# PLLDIG_CTRL register map
Vendor: Texas Instruments
Peripheral module from a debugger description file (folder xwrl64xx).
Registers are 32-bit, read-write, no defined reset value unless marked. A register's access mark holds for its fields unless they carry their own. Offsets are as the file gives them; lines under a group give offsets from that group; [hi:lo] are bit positions; {n}, {i} and the like mark numbered series; 'fields as' and 'values as' point back to an identical list; <NAME> marks a mode.

## PLLDIG_CTRL
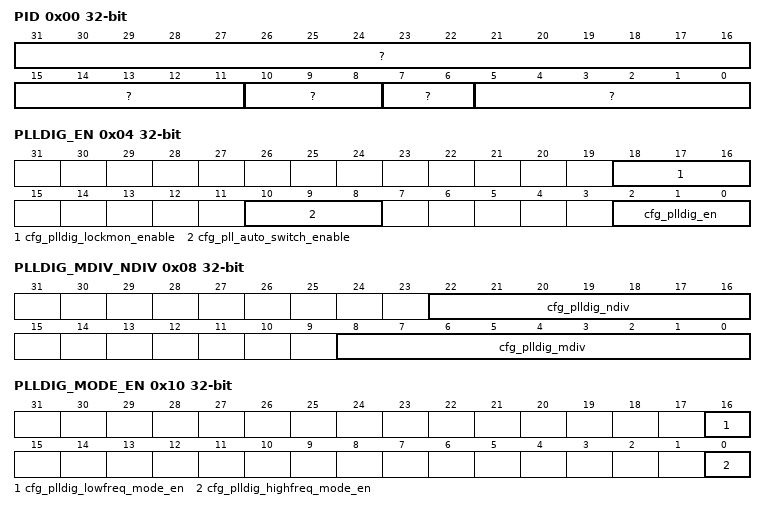
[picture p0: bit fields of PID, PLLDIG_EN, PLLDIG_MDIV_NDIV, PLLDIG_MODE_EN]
0x00 PID ro
  [31:16] ?, [15:11] ?, [10:8] ?, [7:6] ?, [5:0] ?
0x04 PLLDIG_EN
  [18:16] cfg_plldig_lockmon_enable — PLL DIG lockmon enable 0x0 = PLL DIG lockmon disbale 0x7 = PLL DIG lockmon enable
  [10:8] cfg_pll_auto_switch_enable — PLL DIG and APLL auto switch enable 0x0 = PLL DIG wont be auto turn off when APLL is enable 0x7 = PLL DIG will be auto turn off when APLL is enable
  [2:0] cfg_plldig_en — PLL DIG enable 0x0 = PLL DIG disable 0x7 = PLL DIG enable
0x08 PLLDIG_MDIV_NDIV
  [22:16] cfg_plldig_ndiv — NDIV value for the PLL DIG Input clock divider settings .NDIV value directly programs the 7-bit pre- divider. Divide value ranges from 2 to 127. NDIV value has to be chosen based on the REF_CLKIN frequency so as to get the internal reference frequency of the PLL closest to 2Mhz
  [8:0] cfg_plldig_mdiv — MDIV value for the PLL DIG Feedback divider settings. MDIV value directly programs the 9-bit feedback divider. Divide value ranges from 2 to 511. MDIV value has to be chosen to generate the required clock out frequency from the 2Mhz internal PLL reference
0x0C PLLDIG_CTRL
  [31:0] cfg_plldig_ctrl — PLL DIG test controls
0x10 PLLDIG_MODE_EN
  [16] cfg_plldig_lowfreq_mode_en — PLL DIG high frequency mode operation, Divide by 2 the PLL clock out
  [0] cfg_plldig_highfreq_mode_en — PLL DIG high frequency mode operation
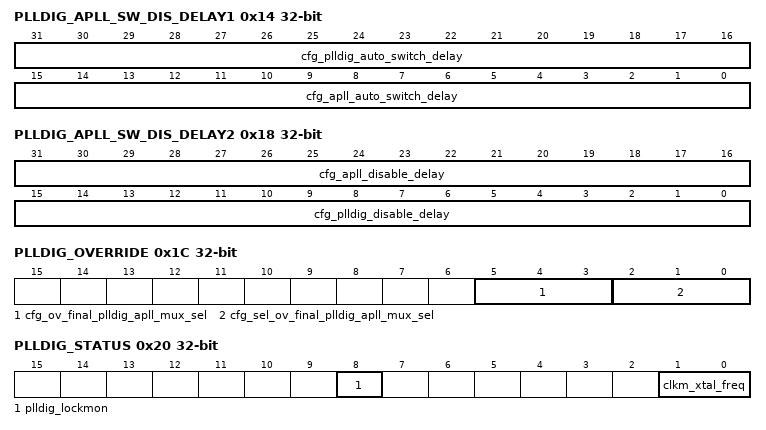
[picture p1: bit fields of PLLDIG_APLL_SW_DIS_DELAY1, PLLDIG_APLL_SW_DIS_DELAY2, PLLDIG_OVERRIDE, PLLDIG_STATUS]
0x14 PLLDIG_APLL_SW_DIS_DELAY1
  [31:16] cfg_plldig_auto_switch_delay — Delay to switch the PLL clock source when the auto PLL switch mode is enable
  [15:0] cfg_apll_auto_switch_delay — Delay to switch the PLL clock source when the auto PLL switch mode is enable
0x18 PLLDIG_APLL_SW_DIS_DELAY2
  [31:16] cfg_apll_disable_delay — Delay between the PLL clock source switching and disabling of the APLL
  [15:0] cfg_plldig_disable_delay — Delay between the PLL clock source switching and disabling of the PLL DIG
0x1C PLLDIG_OVERRIDE
  [5:3] cfg_ov_final_plldig_apll_mux_sel — Override control for the fast clock src mux select 0x0 = PLL DIG selected as fast clock 0x7 = APLL selected as fast clock
  [2:0] cfg_sel_ov_final_plldig_apll_mux_sel — Mux select control to select the override value of the fast clock src mux select 0x0 = functional value selected for the fast clock src mux select 0x7 = Override value selected for the fast clock src mux select
0x20 PLLDIG_STATUS ro
  [8] plldig_lockmon — PLL DIG lockmon status
  [1:0] clkm_xtal_freq — XTAL clock frequency status, 0x0 = 25MHz 0x1 = 40MHz 0x2 = 26MHz 0x3 = 38.4MHz
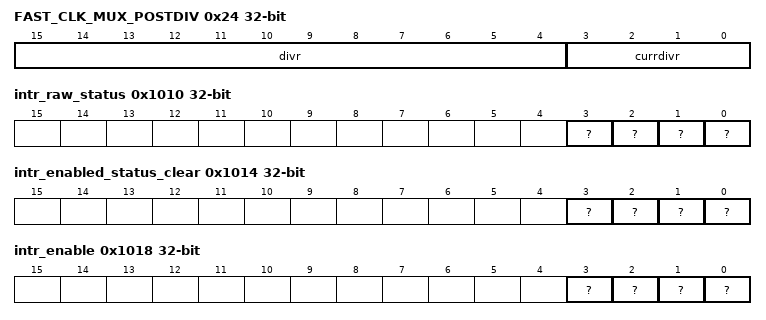
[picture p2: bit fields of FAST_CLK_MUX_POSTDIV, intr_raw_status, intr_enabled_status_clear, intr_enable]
0x24 FAST_CLK_MUX_POSTDIV access per field
  [15:4] divr rw — Divider value for FAST selected clock. Data should be loaded as multibit. For example: if divider value of 8 (1000) needs to be selected then '100010001000' should be configured to the register.
  [3:0] currdivr ro — Status shows the current divider value choosen for FAST_CLK.
0x28 FAST_CLK_STATUS ro
  [1:0] currclk — Current Clock selected by GCM Clock Mux 0x1 : PLLDIG 0x2 : APLL
0x1008 LOCK0_KICK0 — - KICK0 component
  [31:0] ?
0x100C LOCK0_KICK1 — - KICK1 component
  [31:0] ?
0x1010 intr_raw_status — Interrupt Raw Status/Set Register
  [3] ? — Proxy0 access violation error. Raw status is read. Write a 1 to set the status. Writing a 0 has no effect.
  [2] ? — Kick access violation error. Raw status is read. Write a 1 to set the status. Writing a 0 has no effect.
  [1] ? — Addressing violation error. Raw status is read. Write a 1 to set the status. Writing a 0 has no effect.
  [0] ? — Protection violation error. Raw status is read. Write a 1 to set the status. Writing a 0 has no effect.
0x1014 intr_enabled_status_clear — Interrupt Enabled Status/Clear register
  [3] ? — Proxy0 access violation error. Enabled status is read. Write a 1 to clear the status. Writing a 0 has no effect.
  [2] ? — Kick access violation error. Enabled status is read. Write a 1 to clear the status. Writing a 0 has no effect.
  [1] ? — Addressing violation error. Enabled status is read. Write a 1 to clear the status. Writing a 0 has no effect.
  [0] ? — Protection violation error. Enabled status is read. Write a 1 to clear the status. Writing a 0 has no effect.
0x1018 intr_enable — Interrupt Enable register
  [3] ? — Proxy0 access violation error enable. Write a 1 to set the enable. Writing a 0 has no effect.
  [2] ? — Kick access violation error enable. Write a 1 to set the enable. Writing a 0 has no effect.
  [1] ? — Addressing violation error enable. Write a 1 to set the enable. Writing a 0 has no effect.
  [0] ? — Protection violation error enable. Write a 1 to set the enable. Writing a 0 has no effect.
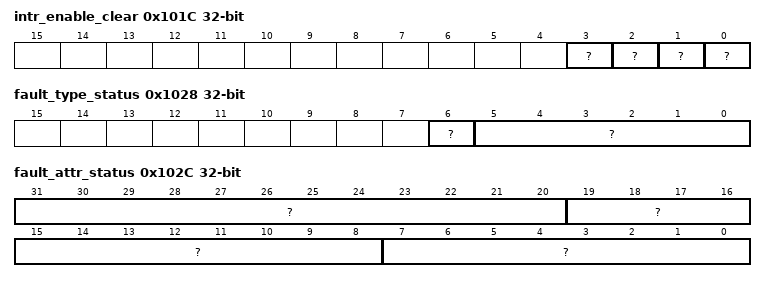
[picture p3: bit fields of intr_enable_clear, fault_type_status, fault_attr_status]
0x101C intr_enable_clear — Interrupt Enable Clear register
  [3] ? — Proxy0 access violation error enable clear. Write a 1 to clear the enable. Writing a 0 has no effect.
  [2] ? — Kick access violation error enable clear. Write a 1 to clear the enable. Writing a 0 has no effect.
  [1] ? — Addressing violation error enable clear. Write a 1 to clear the enable. Writing a 0 has no effect.
  [0] ? — Protection violation error enable clear. Write a 1 to clear the enable. Writing a 0 has no effect.
0x1020 eoi
  [7:0] ? — EOI vector value. Write this with interrupt distribution value in the chip.
0x1024 fault_address ro
  [31:0] ? — Fault Address.
0x1028 fault_type_status ro
  [6] ? — Non-secure access.
  [5:0] ? — Fault Type 10_0000 = Supervisor read fault - priv = 1 dir = 1 dtype != 1 01_0000 = Supervisor write fault - priv = 1 dir = 0 00_1000 = Supervisor execute fault - priv = 1 dir = 1 dtype = 1 00_0100 = User read fault - priv = 0 dir = 1 dtype = 1 00_0010 = User write fault - priv = 0 dir = 0 00_0001 = User execute fault - priv = 0 dir = 1 dtype = 1 00_0000 = No fault
0x102C fault_attr_status ro — Fault Attribute Status register
  [31:20] ? — XID.
  [19:8] ? — Route ID.
  [7:0] ? — Privilege ID.
0x1030 fault_clear wo
  [0] ? — Fault clear. Writing a 1 clears the current fault. Writing a 0 has no effect.
